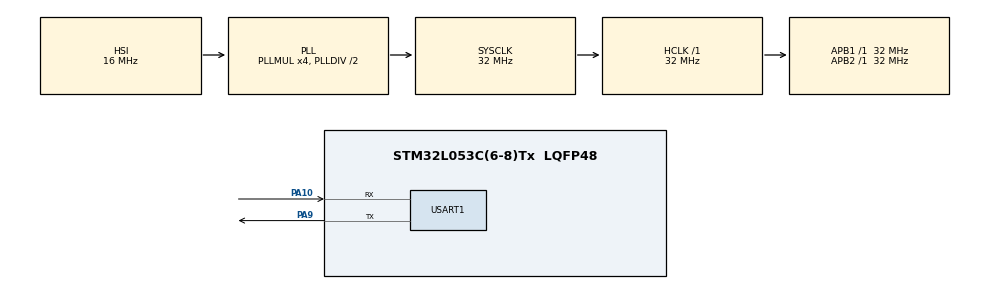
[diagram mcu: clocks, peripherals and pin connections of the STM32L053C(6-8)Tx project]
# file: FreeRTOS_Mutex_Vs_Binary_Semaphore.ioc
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FREERTOS.Tasks01=defaultTask,0,128,StartDefaultTask,Default,NULL,Dynamic,NULL,NULL
Mcu.Family=STM32L0
Mcu.Name=STM32L053C(6-8)Tx
Mcu.Package=LQFP48
NVIC.TIM6_DAC_IRQn=true\:3\:0\:false\:false\:true\:false\:false\:true\:true
NVIC.TimeBase=TIM6_DAC_IRQn
NVIC.TimeBaseIP=TIM6
PA10.Mode=Asynchronous
PA10.Signal=USART1_RX
PA9.Mode=Asynchronous
PA9.Signal=USART1_TX
ProjectManager.HeapSize=0x200
ProjectManager.StackSize=0x400
ProjectManager.TargetToolchain=STM32CubeIDE
RCC.AHBFreq_Value=32000000
RCC.APB1Freq_Value=32000000
RCC.APB1TimFreq_Value=32000000
RCC.APB2Freq_Value=32000000
RCC.APB2TimFreq_Value=32000000
RCC.HCLKFreq_Value=32000000
RCC.HSE_VALUE=8000000
RCC.HSI16_VALUE=16000000
RCC.HSI48MClockSelection=RCC_USBCLKSOURCE_HSI48
RCC.HSI48_VALUE=48000000
RCC.HSI_VALUE=16000000
RCC.LSE_VALUE=32768
RCC.MSI_VALUE=2097000
RCC.PLLMUL=RCC_PLLMUL_4
RCC.RTCClockSelectionVirtual=RCC_RTCCLKSOURCE_LSE
RCC.SYSCLKFreq_VALUE=32000000
RCC.SYSCLKSource=RCC_SYSCLKSOURCE_PLLCLK
RCC.VCOOutputFreq_Value=64000000
USART1.VirtualMode-Asynchronous=VM_ASYNC
VP_FREERTOS_VS_CMSIS_V1.Mode=CMSIS_V1
VP_SYS_VS_tim6.Mode=TIM6
board=STM32L0538-DISCO

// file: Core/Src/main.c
/* USER CODE BEGIN Header */
/**
  ******************************************************************************
  * @file           : main.c
  * @brief          : Main program body
  ******************************************************************************
  * @attention
  *
  * Copyright (c) 2023 STMicroelectronics.
  * All rights reserved.
  *
  * This software is licensed under terms that can be found in the LICENSE file
  * in the root directory of this software component.
  * If no LICENSE file comes with this software, it is provided AS-IS.
  *
  ******************************************************************************
  */
/* USER CODE END Header */
#include "main.h"
//#include "cmsis_os.h"

/* USER CODE BEGIN Includes */

#include "FreeRTOS.h"
#include "task.h"
#include "timers.h"
#include "queue.h"
#include "semphr.h"
#include "event_groups.h"

#include "string.h"
#include <stdio.h>
/* USER CODE END Includes */

UART_HandleTypeDef huart1;

void SystemClock_Config(void);
static void MX_GPIO_Init(void);
static void MX_USART1_UART_Init(void);

/* USER CODE BEGIN 0 */

/*********** Create Simple Mutex Handler ***************/
SemaphoreHandle_t SimpleMutex;
SemaphoreHandle_t binSemaphore;

/*********** Create Task Handler ***************/
TaskHandle_t HPT_Handler;
TaskHandle_t MPT_Handler;
TaskHandle_t LPT_Handler;

/*********** Create Task functions ***************/
void HPT_Task(void *argument);
void MPT_Task(void *argument);
void LPT_Task(void *argument);

/*********** Create Send_UART functions ***************/
void Send_Uart(char *str) {
	xSemaphoreTake(SimpleMutex, portMAX_DELAY);
	HAL_UART_Transmit(&huart1, (uint8_t*) str, strlen(str), HAL_MAX_DELAY);
	HAL_Delay(1000);
	xSemaphoreGive(SimpleMutex);
}

void Send_Uart2(char *str) {
	xSemaphoreTake(binSemaphore, portMAX_DELAY);
	HAL_Delay(2000);

	HAL_UART_Transmit(&huart1, (uint8_t*) "\r\nUsing Semaphore\r\n", 19,
	    				1000);
	HAL_UART_Transmit(&huart1, (uint8_t*) str, strlen(str), HAL_MAX_DELAY);
	xSemaphoreGive(binSemaphore);
}

/* USER CODE END 0 */

int main(void)
{

  /* MCU Configuration--------------------------------------------------------*/

  /* Reset of all peripherals, Initializes the Flash interface and the Systick. */
  HAL_Init();

  /* Configure the system clock */
  SystemClock_Config();

  /* Initialize all configured peripherals */
  MX_GPIO_Init();
  MX_USART1_UART_Init();
  /* USER CODE BEGIN 2 */

  /*********** Create Simple Mutex ***************/
  	SimpleMutex = xSemaphoreCreateMutex();

  	if (SimpleMutex != NULL)
  		HAL_UART_Transmit(&huart1, (uint8_t*) "Mutex Created\r\n\r\n", 17,
  				1000);
  	else
  		HAL_UART_Transmit(&huart1, (uint8_t*) "Mutex not Created\r\n\r\n", 21,
  				1000);

    /*********** Create Simple binSemaphore ***************/
    	binSemaphore = xSemaphoreCreateBinary();

    	if (SimpleMutex != NULL)
    		HAL_UART_Transmit(&huart1, (uint8_t*) "Semaphore Created\r\n\r\n", 21,
    				1000);
    	else
    		HAL_UART_Transmit(&huart1, (uint8_t*) "Semaphore not Created\r\n\r\n", 25,
    				1000);

    	xSemaphoreGive(binSemaphore);
  	/*********** Create Task ***************/
  	xTaskCreate(HPT_Task, "HPT", 128, NULL, 3, &HPT_Handler);
  	xTaskCreate(MPT_Task, "MPT", 128, NULL, 2, &MPT_Handler);
  	xTaskCreate(LPT_Task, "LPT", 128, NULL, 1, &LPT_Handler);

  	/*********** Create Task Scheduler ***************/
  	vTaskStartScheduler();\

  /* USER CODE END 2 */

  /* Infinite loop */
  while (1)
  {

  }
}

void SystemClock_Config(void)
{
  RCC_OscInitTypeDef RCC_OscInitStruct = {0};
  RCC_ClkInitTypeDef RCC_ClkInitStruct = {0};
  RCC_PeriphCLKInitTypeDef PeriphClkInit = {0};

  /** Configure the main internal regulator output voltage
  */
  __HAL_PWR_VOLTAGESCALING_CONFIG(PWR_REGULATOR_VOLTAGE_SCALE1);

  /** Initializes the RCC Oscillators according to the specified parameters
  * in the RCC_OscInitTypeDef structure.
  */
  RCC_OscInitStruct.OscillatorType = RCC_OSCILLATORTYPE_HSI;
  RCC_OscInitStruct.HSIState = RCC_HSI_ON;
  RCC_OscInitStruct.HSICalibrationValue = RCC_HSICALIBRATION_DEFAULT;
  RCC_OscInitStruct.PLL.PLLState = RCC_PLL_ON;
  RCC_OscInitStruct.PLL.PLLSource = RCC_PLLSOURCE_HSI;
  RCC_OscInitStruct.PLL.PLLMUL = RCC_PLLMUL_4;
  RCC_OscInitStruct.PLL.PLLDIV = RCC_PLLDIV_2;
  if (HAL_RCC_OscConfig(&RCC_OscInitStruct) != HAL_OK)
  {
    Error_Handler();
  }

  /** Initializes the CPU, AHB and APB buses clocks
  */
  RCC_ClkInitStruct.ClockType = RCC_CLOCKTYPE_HCLK|RCC_CLOCKTYPE_SYSCLK
                              |RCC_CLOCKTYPE_PCLK1|RCC_CLOCKTYPE_PCLK2;
  RCC_ClkInitStruct.SYSCLKSource = RCC_SYSCLKSOURCE_PLLCLK;
  RCC_ClkInitStruct.AHBCLKDivider = RCC_SYSCLK_DIV1;
  RCC_ClkInitStruct.APB1CLKDivider = RCC_HCLK_DIV1;
  RCC_ClkInitStruct.APB2CLKDivider = RCC_HCLK_DIV1;

  if (HAL_RCC_ClockConfig(&RCC_ClkInitStruct, FLASH_LATENCY_1) != HAL_OK)
  {
    Error_Handler();
  }
  PeriphClkInit.PeriphClockSelection = RCC_PERIPHCLK_USART1;
  PeriphClkInit.Usart1ClockSelection = RCC_USART1CLKSOURCE_PCLK2;
  if (HAL_RCCEx_PeriphCLKConfig(&PeriphClkInit) != HAL_OK)
  {
    Error_Handler();
  }
}

static void MX_USART1_UART_Init(void)
{

  huart1.Instance = USART1;
  huart1.Init.BaudRate = 115200;
  huart1.Init.WordLength = UART_WORDLENGTH_8B;
  huart1.Init.StopBits = UART_STOPBITS_1;
  huart1.Init.Parity = UART_PARITY_NONE;
  huart1.Init.Mode = UART_MODE_TX_RX;
  huart1.Init.HwFlowCtl = UART_HWCONTROL_NONE;
  huart1.Init.OverSampling = UART_OVERSAMPLING_16;
  huart1.Init.OneBitSampling = UART_ONE_BIT_SAMPLE_DISABLE;
  huart1.AdvancedInit.AdvFeatureInit = UART_ADVFEATURE_NO_INIT;
  if (HAL_UART_Init(&huart1) != HAL_OK)
  {
    Error_Handler();
  }

}

static void MX_GPIO_Init(void)
{

  /* GPIO Ports Clock Enable */
  __HAL_RCC_GPIOA_CLK_ENABLE();

}

/* USER CODE BEGIN 4 */
void HPT_Task(void *argument) {

	char *strtosend = "\r\n\r\nIN HPT|-|_|-|_|-|_|-|_|-|_|-|_|-|_|-|_|-|\r\n\r\n\r\n";
	while (1) {
		char *str1 = "Entered HPT and about to take Mutex.\r\n";
		HAL_UART_Transmit(&huart1, (uint8_t*) str1, strlen(str1),
				HAL_MAX_DELAY);

		Send_Uart(strtosend);
		Send_Uart2(strtosend);

		char *str2 = "Leaving HPT.\r\n\r\n";
		HAL_UART_Transmit(&huart1, (uint8_t*) str2, strlen(str2),
				HAL_MAX_DELAY);

		vTaskDelay(1000);
	}

}
void MPT_Task(void *argument) {

	char *strtosend = "\r\n\r\nIN MPT<^>v<^>v<^>v<^>v<^>v<^>v<^>v<^>v<^>\r\n\r\n\r\n";
	while (1) {
		char *str1 = "Entered MPT and about to take Mutex.\r\n";
		HAL_UART_Transmit(&huart1, (uint8_t*) str1, strlen(str1),
				HAL_MAX_DELAY);

		Send_Uart(strtosend);
		Send_Uart2(strtosend);

		char *str2 = "Leaving MPT.\r\n\r\n";
		HAL_UART_Transmit(&huart1, (uint8_t*) str2, strlen(str2),
				HAL_MAX_DELAY);

		vTaskDelay(1000);
	}
}
void LPT_Task(void *argument) {

	char *strtosend = "\r\n\r\nIN LPT*-_-*-_-*-_-*-_-*-_-*-_-*\r\n\r\n\r\n";
	while (1) {
		char *str1 = "Entered LPT and about to take Mutex.\r\n";
		HAL_UART_Transmit(&huart1, (uint8_t*) str1, strlen(str1),
				HAL_MAX_DELAY);

		Send_Uart(strtosend);
		Send_Uart2(strtosend);

		char *str2 = "Leaving LPT.\r\n\r\n";
		HAL_UART_Transmit(&huart1, (uint8_t*) str2, strlen(str2),
				HAL_MAX_DELAY);

		vTaskDelay(1000);
	}
}

	/*********** Output of one cycle ***************/

//Mutex Created
//
//Semaphore Created
//
//Entered HPT and about to take Mutex.
//
//
//IN HPT|-|_|-|_|-|_|-|_|-|_|-|_|-|_|-|_|-|
//
//
//
//Using Semaphore
//
//
//IN HPT|-|_|-|_|-|_|-|_|-|_|-|_|-|_|-|_|-|
//
//
//Leaving HPT.
//
//Entered MPT and about to take Mutex.
//
//
//IN MPT<^>v<^>v<^>v<^>v<^>v<^>v<^>v<^>v<^>
//
//
//Entered HPT and about to take Mutex.
//
//
//IN HPT|-|_|-|_|-|_|-|_|-|_|-|_|-|_|-|_|-|
//
//
//
//Using Semaphore
//
//
//IN HPT|-|_|-|_|-|_|-|_|-|_|-|_|-|_|-|_|-|
//
//
//Leaving HPT.
//
//Entered HPT and about to take Mutex.
//
//
//IN HPT|-|_|-|_|-|_|-|_|-|_|-|_|-|_|-|_|-|
//
//
//
//Using Semaphore
//
//
//IN MPT<^>v<^>v<^>v<^>v<^>v<^>v<^>v<^>v<^>
//
//
//
//Using Semaphore
//
//
//IN HPT|-|_|-|_|-|_|-|_|-|_|-|_|-|_|-|_|-|
//
//
//Leaving HPT.
//
//Leaving MPT.
//
//Entered LPT and about to take Mutex.
//
//
//IN LPT*-_-*-_-*-_-*-_-*-_-*-_-*
//
//
//Entered HPT and about to take Mutex.
//
//
//IN HPT|-|_|-|_|-|_|-|_|-|_|-|_|-|_|-|_|-|
//
//
//
//Using Semaphore
//
//
//IN HPT|-|_|-|_|-|_|-|_|-|_|-|_|-|_|-|_|-|
//
//
//Leaving HPT.
//
//Entered MPT and about to take Mutex.
//
//
//IN MPT<^>v<^>v<^>v<^>v<^>v<^>v<^>v<^>v<^>
//
//
//Entered HPT and about to take Mutex.
//
//
//IN HPT|-|_|-|_|-|_|-|_|-|_|-|_|-|_|-|_|-|
//
//
//
//Using Semaphore
//
//
//IN HPT|-|_|-|_|-|_|-|_|-|_|-|_|-|_|-|_|-|
//
//
//Leaving HPT.
//
//Entered HPT and about to take Mutex.
//
//
//IN HPT|-|_|-|_|-|_|-|_|-|_|-|_|-|_|-|_|-|
//
//
//
//Using Semaphore
//
//
//IN MPT<^>v<^>v<^>v<^>v<^>v<^>v<^>v<^>v<^>
//
//
//
//Using Semaphore
//
//
//IN HPT|-|_|-|_|-|_|-|_|-|_|-|_|-|_|-|_|-|
//
//
//Leaving HPT.
//
//Leaving MPT.
//
//Entered HPT and about to take Mutex.
//
//
//IN HPT|-|_|-|_|-|_|-|_|-|_|-|_|-|_|-|_|-|
//
//
//Entered MPT and about to take Mutex.
//
//
//IN MPT<^>v<^>v<^>v<^>v<^>v<^>v<^>v<^>v<^>
//
//
//
//Using Semaphore
//
//
//IN LPT*-_-*-_-*-_-*-_-*-_-*-_-*
//
//
//
//Using Semaphore
//
//
//IN HPT|-|_|-|_|-|_|-|_|-|_|-|_|-|_|-|_|-|
//
//
//Leaving HPT.
//
//Entered HPT and about to take Mutex.
//
//
//IN HPT|-|_|-|_|-|_|-|_|-|_|-|_|-|_|-|_|-|
//
//
//
//Using Semaphore
//
//
//IN MPT<^>v<^>v<^>v<^>v<^>v<^>v<^>v<^>v<^>
//
//
//
//Using Semaphore
//
//
//IN HPT|-|_|-|_|-|_|-|_|-|_|-|_|-|_|-|_|-|
//
//
//Leaving HPT.
//
//Leaving MPT.
//
//Leaving LPT.

/* USER CODE END 4 */

void HAL_TIM_PeriodElapsedCallback(TIM_HandleTypeDef *htim)
{
  if (htim->Instance == TIM6) {
    HAL_IncTick();
  }
}

void Error_Handler(void)
{
  __disable_irq();
  while (1)
  {
  }
}
